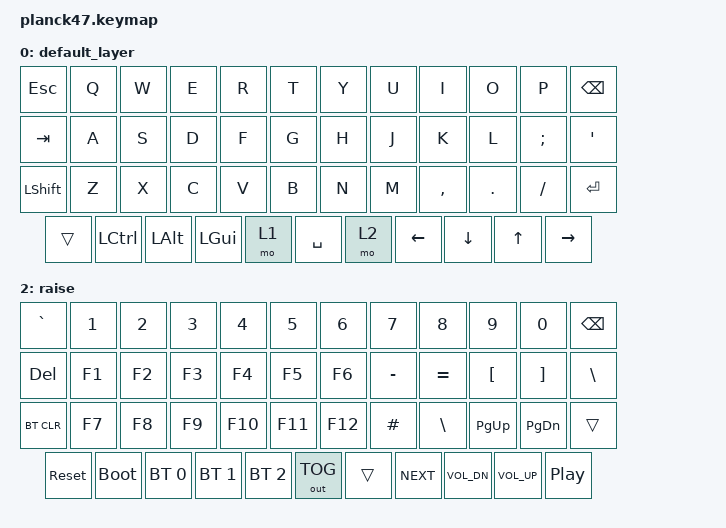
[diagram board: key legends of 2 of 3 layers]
#include <behaviors.dtsi>
#include <dt-bindings/zmk/keys.h>
#include <dt-bindings/zmk/bt.h>
#include <dt-bindings/zmk/outputs.h>

/ {
    keymap {
        compatible = "zmk,keymap";

        default_layer {
            bindings = <
                &kp ESC    &kp Q    &kp W    &kp E    &kp R    &kp T    &kp Y    &kp U    &kp I     &kp O      &kp P      &kp BSPC
                &kp TAB    &kp A    &kp S    &kp D    &kp F    &kp G    &kp H    &kp J    &kp K     &kp L      &kp SEMI   &kp QUOT
                &kp LSHIFT   &kp Z    &kp X    &kp C    &kp V    &kp B    &kp N    &kp M    &kp COMMA &kp DOT    &kp FSLH   &kp RET
                &trans   &kp LCTRL &kp LALT &kp LGUI &mo 1 &kp SPACE &mo 2 &kp LEFT &kp DOWN &kp UP &kp RIGHT
            >;
        };

        lower {
            bindings = <
                &kp LS(GRAVE) &kp LS(N1) &kp LS(N2) &kp LS(N3) &kp LS(N4) &kp LS(N5) &kp LS(N6) &kp LS(N7) &kp LS(N8) &kp LS(N9) &kp LS(N0) &kp DEL
                &kp DEL &kp F1 &kp F2 &kp F3 &kp F4 &kp F5 &kp F6 &kp UNDER &kp PLUS &kp LBRC &kp RBRC &kp PIPE
                &bt BT_CLR_ALL &kp F7 &kp F8 &kp F9 &kp F10 &kp F11 &kp F12 &kp LS(HASH) &kp LS(BSLH) &kp HOME &kp END &trans
                &trans &trans &trans &trans &trans &trans &trans &trans &kp C_NEXT &kp C_VOL_DN &kp C_VOL_UP &kp C_PP
            >;
        };
        raise {
            bindings = <
                &kp GRAVE &kp N1 &kp N2 &kp N3 &kp N4 &kp N5 &kp N6 &kp N7 &kp N8 &kp N9 &kp N0 &kp BSPC
                &kp DEL &kp F1 &kp F2 &kp F3 &kp F4 &kp F5 &kp F6 &kp MINUS &kp EQUAL &kp LBKT &kp RBKT &kp BSLH
                &bt BT_CLR &kp F7 &kp F8 &kp F9 &kp F10 &kp F11 &kp F12 &kp HASH &kp BSLH &kp PG_UP &kp PG_DN &trans
                &sys_reset &bootloader &bt BT_SEL 0 &bt BT_SEL 1 &bt BT_SEL 2 &out OUT_TOG &trans &kp C_NEXT &kp C_VOL_DN &kp C_VOL_UP &kp C_PP
            >;
        };

   };
};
